# S32K312_M7 register map
Vendor: NXP Semiconductors; File version: 1.4
CPU: CM7 r0p1, little endian, MPU, FPU, VTOR, 4 interrupt priority bits
Registers are 32-bit, read-write, reset 0x0 unless marked. A register's access mark holds for its fields unless they carry their own. Offsets are from the block's base; [hi:lo] are bit positions; lines under a group give offsets from that group; {n}, {i} and the like mark numbered series.

## PFLASH
Base 0x40268000
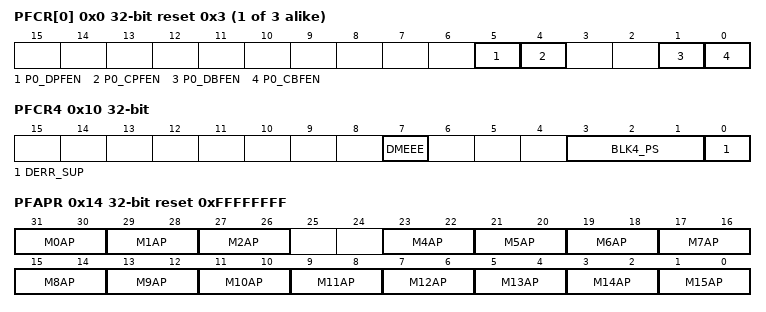
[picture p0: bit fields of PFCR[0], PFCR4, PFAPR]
{0x0+4i} PFCR[{i}] (i=0..2) reset 0x3 — Platform Flash Memory Configuration i
  [5] P0_DPFEN — Port0 Data Prefetch Enable
    0=bfv_P0_DPFEN_0 (Disable); 1=bfv_P0_DPFEN_1 (Enable)
  [4] P0_CPFEN — Port0 Code Prefetch Enable
    0=bfv_P0_CPFEN_0 (Disable); 1=bfv_P0_CPFEN_1 (Enable)
  [1] P0_DBFEN — Port0 PFLASH Line Read Data Buffers Enable
    0=bfv_P0_DBFEN_0 (Disable); 1=bfv_P0_DBFEN_1 (Enable)
  [0] P0_CBFEN — Port0 PFLASH Line Read Code Buffers Enable
    0=bfv_P0_CBFEN_0 (Disable); 1=bfv_P0_CBFEN_1 (Enable)
0x10 PFCR4 — Platform Flash Memory Configuration 4
  [7] DMEEE — Disable Multi-Bit ECC Error Exception
    0=bfv_DMEEE_0 (Error response sent on system bus for multi-bit ECC error); 1=bfv_DMEEE_1 (Error response not sent on system bus for multi-bit ECC error)
  [3:1] BLK4_PS — Block 4 Pipe Select
    0=bfv_BLK4_PS_000 (Block 4 access is always through pipe0); 1=bfv_BLK4_PS_001 (Block 4 access is always through pipe1); 2=bfv_BLK4_PS_010 (Block 4 access is always through pipe2); 3=bfv_BLK4_PS_011 (Block 4 access is always through pipe3); 0b1xx=bfv_BLK4_PS_1xx (Block 4 access can be through any of the command pipes, based on which command pipe is available for block 4 access)
  [0] DERR_SUP — Data Error Suppression
    0=bfv_DERR_SUP_0 (Reports ECC events on data flash memory accesses); 1=bfv_DERR_SUP_1 (Single-bit and multi-bit ECC events on data flash memory accesses are suppressed)
0x14 PFAPR reset 0xFFFFFFFF — Platform Flash Memory Access Protection
  [all] fields
    0bx0=ACCESS_NO (This master cannot perform any read accesses); 0bx1=ACCESS_YES (This master can perform read accesses)
  [31:30] M0AP — Master n Access Protection
  [29:28] M1AP — Master n Access Protection
  [27:26] M2AP — Master n Access Protection
  [31-2n:30-2n] M{n}AP (n=4..15) — Master n Access Protection
0x300 PFCPGM_PEADR_L — Platform Flash Memory Program Erase Address Logical
  [31:0] PEADR_L — Program Erase Address Logical
0x304 PFCPGM_PEADR_P ro — Platform Flash Memory Program Erase Address Physical
  [31:0] PEADR_P — Program Erase Address Physical
0x308 PFCPGM_XPEADR_L — Platform Flash Memory Express Program Erase Address Logical
  [31:0] XPEADR_L — Express Program Erase Address Logical
0x30C PFCPGM_XPEADR_P ro — Platform Flash Memory Express Program Erase Address Physical
  [31:0] XPEADR_P — Express Program Erase Address Physical
{0x340+4i} PFCBLK_SPELOCK[{i}] (i=0..2) reset 0xFFFFFFFF — Block n Sector Program Erase Lock
  [31:0] SLCK — Sector Lock
0x358 PFCBLKU_SPELOCK reset 0x1 — Block UTEST Sector Program Erase Lock
  [0] SLCK — Sector Lock
{0x35C+4i} PFCBLK_SSPELOCK[{i}] (i=0..1) reset 0xFFF — Block n Super Sector Program Erase Lock
  [11:0] SSLCK — Super Sector Lock
{0x380+4i} PFCBLK_SETSLOCK[{i}] (i=0..2) — Block n Set Sector Lock
  [31:0] SETSLCK — If the vector bit value = 0, the corresponding lock bit is not owned by any master
0x398 PFCBLKU_SETSLOCK — Block UTEST Set Sector Lock
  [0] SETSLCK — Set Sector Lock
{0x39C+4i} PFCBLK_SSETSLOCK[{i}] (i=0..1) — Block n Set Super Sector Lock
  [11:0] SSETSLCK — Set Super Sector Lock
{0x3C0+0x20*i} PFCBLKi_LOCKMASTER_S[{i}] (i=0..2) group
  {0x0+4j} PFCBLK_LOCKMASTER_S[{j}] (j=0..7) ro reset 0xFFFFFFFF — Block a Lock Master Sector b
    [31:0] LOCKMASTER_S
0x480 PFCBLKU_LOCKMASTER_S ro reset 0xFF — Block UTEST Lock Master Sector
  [7:0] LOCKMASTER_S — Lock Master Sector
{0x484+0x10*i} PFCBLKi_LOCKMASTER_SS[{i}] (i=0..1) group
  {0x0+4j} PFCBLK_LOCKMASTER_SS{j} (j=0..2) ro reset 0xFFFFFFFF — Block m Lock Master Super Sector n
    [31:0] LOCKMASTER_SS — Block a Lock Master Super Sector b
